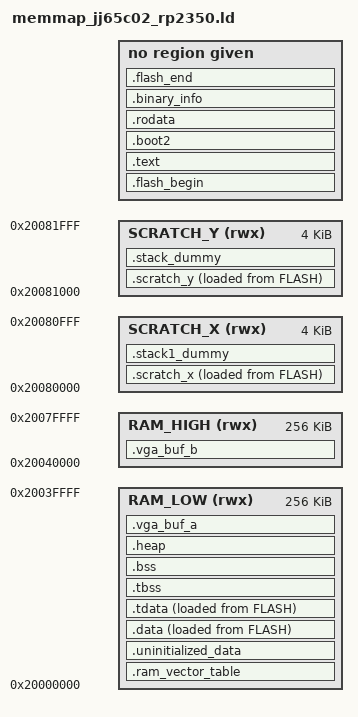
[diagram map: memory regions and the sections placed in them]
/*
 * Custom RP2350 memory map for JJ65c02 pico_core.
 *
 * Splits main 512 KB SRAM into two halves so the two VGA framebuffers can
 * live in different striped regions:
 *
 *   RAM_LOW  : 0x20000000 .. 0x20040000   (SRAM banks 0..3, 4-byte striped)
 *   RAM_HIGH : 0x20040000 .. 0x20080000   (SRAM banks 4..7, 4-byte striped)
 *
 * Reads from RAM_HIGH and reads/writes to RAM_LOW go to physically distinct
 * bus targets, so a scanout DMA continuously pulling from one buffer does
 * not contend with the CPU/copy DMA writing the other buffer.
 *
 * Layout:
 *   .data, .bss, .heap         -> RAM_LOW
 *   .vga_buf_a (show or draw)  -> RAM_LOW (placed at the very top of RAM_LOW
 *                                          via __vga_buf_a -- see below)
 *   .vga_buf_b (the other buf) -> RAM_HIGH
 *
 * We deliberately put .vga_buf_a near the top of RAM_LOW so that the heap
 * has unbroken room from __end__ to the buffer's base. .vga_buf_b sits at
 * the bottom of RAM_HIGH; the rest of RAM_HIGH remains unused (a future
 * enhancement: a small extra heap region living in RAM_HIGH).
 *
 * Based on pico-sdk's src/rp2_common/pico_crt0/rp2350/memmap_default.ld.
 */

MEMORY
{
    INCLUDE "pico_flash_region.ld"
    RAM_LOW(rwx)   : ORIGIN = 0x20000000, LENGTH = 256k
    RAM_HIGH(rwx)  : ORIGIN = 0x20040000, LENGTH = 256k
    SCRATCH_X(rwx) : ORIGIN = 0x20080000, LENGTH = 4k
    SCRATCH_Y(rwx) : ORIGIN = 0x20081000, LENGTH = 4k
}

ENTRY(_entry_point)

SECTIONS
{
    .flash_begin : {
        __flash_binary_start = .;
    } > FLASH

    .text : {
        __logical_binary_start = .;
        KEEP (*(.vectors))
        KEEP (*(.binary_info_header))
        __binary_info_header_end = .;
        KEEP (*(.embedded_block))
        __embedded_block_end = .;
        KEEP (*(.reset))
        *(.init)
        *libgcc.a:cmse_nonsecure_call.o
        *(EXCLUDE_FILE(*libgcc.a: *libc.a:*lib_a-mem*.o *libm.a:) .text*)
        *(.fini)
        *crtbegin.o(.ctors)
        *crtbegin?.o(.ctors)
        *(EXCLUDE_FILE(*crtend?.o *crtend.o) .ctors)
        *(SORT(.ctors.*))
        *(.ctors)
        *crtbegin.o(.dtors)
        *crtbegin?.o(.dtors)
        *(EXCLUDE_FILE(*crtend?.o *crtend.o) .dtors)
        *(SORT(.dtors.*))
        *(.dtors)

        . = ALIGN(4);
        PROVIDE_HIDDEN (__preinit_array_start = .);
        KEEP(*(SORT(.preinit_array.*)))
        KEEP(*(.preinit_array))
        PROVIDE_HIDDEN (__preinit_array_end = .);

        . = ALIGN(4);
        PROVIDE_HIDDEN (__init_array_start = .);
        KEEP(*(SORT(.init_array.*)))
        KEEP(*(.init_array))
        PROVIDE_HIDDEN (__init_array_end = .);

        . = ALIGN(4);
        PROVIDE_HIDDEN (__fini_array_start = .);
        *(SORT(.fini_array.*))
        *(.fini_array)
        PROVIDE_HIDDEN (__fini_array_end = .);

        *(.eh_frame*)
        . = ALIGN(4);
    } > FLASH

    .boot2 : {
        __boot2_start__ = .;
        *(.boot2)
        __boot2_end__ = .;
    } > FLASH

    ASSERT(__boot2_end__ - __boot2_start__ <= 256,
        "ERROR: Pico second stage bootloader must be no more than 256 bytes in size")

    .rodata : {
        *(EXCLUDE_FILE(*libgcc.a: *libc.a:*lib_a-mem*.o *libm.a:) .rodata*)
        *(.srodata*)
        . = ALIGN(4);
        *(SORT_BY_ALIGNMENT(SORT_BY_NAME(.flashdata*)))
        . = ALIGN(4);
    } > FLASH

    .ARM.extab :
    {
        *(.ARM.extab* .gnu.linkonce.armextab.*)
    } > FLASH

    __exidx_start = .;
    .ARM.exidx :
    {
        *(.ARM.exidx* .gnu.linkonce.armexidx.*)
    } > FLASH
    __exidx_end = .;

    . = ALIGN(4);
    __binary_info_start = .;
    .binary_info :
    {
        KEEP(*(.binary_info.keep.*))
        *(.binary_info.*)
    } > FLASH
    __binary_info_end = .;
    . = ALIGN(4);

    .ram_vector_table (NOLOAD): {
        *(.ram_vector_table)
    } > RAM_LOW

    .uninitialized_data (NOLOAD): {
        . = ALIGN(4);
        *(.uninitialized_data*)
    } > RAM_LOW

    .data : {
        __data_start__ = .;
        *(vtable)

        *(.time_critical*)

        *(.text*)
        . = ALIGN(4);
        *(.rodata*)
        . = ALIGN(4);

        *(.data*)
        *(.sdata*)

        . = ALIGN(4);
        *(.after_data.*)
        . = ALIGN(4);
        PROVIDE_HIDDEN (__mutex_array_start = .);
        KEEP(*(SORT(.mutex_array.*)))
        KEEP(*(.mutex_array))
        PROVIDE_HIDDEN (__mutex_array_end = .);

        *(.jcr)
        . = ALIGN(4);
    } > RAM_LOW AT> FLASH

    .tdata : {
        . = ALIGN(4);
        *(.tdata .tdata.* .gnu.linkonce.td.*)
        __tdata_end = .;
    } > RAM_LOW AT> FLASH
    PROVIDE(__data_end__ = .);

    __etext = LOADADDR(.data);

    .tbss (NOLOAD) : {
        . = ALIGN(4);
        __bss_start__ = .;
        __tls_base = .;
        *(.tbss .tbss.* .gnu.linkonce.tb.*)
        *(.tcommon)

        __tls_end = .;
    } > RAM_LOW

    .bss (NOLOAD) : {
        . = ALIGN(4);
        __tbss_end = .;

        *(SORT_BY_ALIGNMENT(SORT_BY_NAME(.bss*)))
        *(COMMON)
        PROVIDE(__global_pointer$ = . + 2K);
        *(.sbss*)
        . = ALIGN(4);
        __bss_end__ = .;
    } > RAM_LOW

    .heap (NOLOAD):
    {
        __end__ = .;
        end = __end__;
        KEEP(*(.heap*))
    } > RAM_LOW

    /*
     * VGA show/draw framebuffer A: lives at the top of RAM_LOW.
     * Sized at 153600 bytes; aligned to a cache-line-ish boundary.
     */
    .vga_buf_a (NOLOAD) :
    {
        . = ALIGN(32);
        __vga_buf_a_start = .;
        KEEP(*(.vga_buf_a))
        . = ALIGN(4);
        __vga_buf_a_end = .;
    } > RAM_LOW

    __HeapLimit = __vga_buf_a_start;

    /*
     * VGA show/draw framebuffer B: lives at the base of RAM_HIGH so that
     * scanout DMA reads of one buffer and CPU writes to the other hit
     * physically distinct SRAM banks.
     */
    .vga_buf_b (NOLOAD) :
    {
        . = ALIGN(32);
        __vga_buf_b_start = .;
        KEEP(*(.vga_buf_b))
        . = ALIGN(4);
        __vga_buf_b_end = .;
    } > RAM_HIGH

    .scratch_x : {
        __scratch_x_start__ = .;
        *(.scratch_x.*)
        . = ALIGN(4);
        __scratch_x_end__ = .;
    } > SCRATCH_X AT > FLASH
    __scratch_x_source__ = LOADADDR(.scratch_x);

    .scratch_y : {
        __scratch_y_start__ = .;
        *(.scratch_y.*)
        . = ALIGN(4);
        __scratch_y_end__ = .;
    } > SCRATCH_Y AT > FLASH
    __scratch_y_source__ = LOADADDR(.scratch_y);

    .stack1_dummy (NOLOAD):
    {
        KEEP(*(.stack1*))
    } > SCRATCH_X
    .stack_dummy (NOLOAD):
    {
        KEEP(*(.stack*))
    } > SCRATCH_Y

    .flash_end : {
        KEEP(*(.embedded_end_block*))
        PROVIDE(__flash_binary_end = .);
    } > FLASH =0xaa

    __StackOneTop = ORIGIN(SCRATCH_X) + LENGTH(SCRATCH_X);
    __StackTop = ORIGIN(SCRATCH_Y) + LENGTH(SCRATCH_Y);
    __StackOneBottom = __StackOneTop - SIZEOF(.stack1_dummy);
    __StackBottom = __StackTop - SIZEOF(.stack_dummy);
    PROVIDE(__stack = __StackTop);

    /* Put the linker-script-defined StackLimit at the cap of RAM_LOW so
       sbrk-based heap growth stops before colliding with .vga_buf_a. */
    __StackLimit = __vga_buf_a_start;

    PROVIDE (__heap_start = __end__);
    PROVIDE (__heap_end = __HeapLimit);
    PROVIDE( __tls_align = MAX(ALIGNOF(.tdata), ALIGNOF(.tbss)) );
    PROVIDE( __tls_size_align = (__tls_size + __tls_align - 1) & ~(__tls_align - 1));
    PROVIDE( __arm32_tls_tcb_offset = MAX(8, __tls_align) );

    PROVIDE (_end = __end__);
    PROVIDE (__llvm_libc_heap_limit = __HeapLimit);

    ASSERT(__StackLimit >= __HeapLimit, "region RAM_LOW overflowed")
    ASSERT(__vga_buf_b_end <= ORIGIN(RAM_HIGH) + LENGTH(RAM_HIGH), "region RAM_HIGH overflowed")

    ASSERT( __binary_info_header_end - __logical_binary_start <= 1024, "Binary info must be in first 1024 bytes of the binary")
    ASSERT( __embedded_block_end - __logical_binary_start <= 4096, "Embedded block must be in first 4096 bytes of the binary")
}
